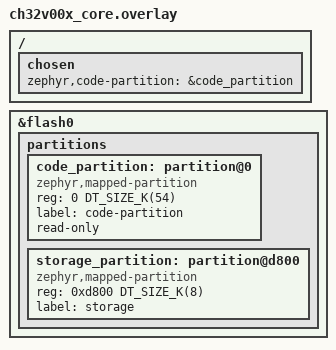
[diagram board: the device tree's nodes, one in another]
/*
 * SPDX-FileCopyrightText: Copyright Michael Hope <michaelh@juju.nz>
 *
 * SPDX-License-Identifier: Apache-2.0
 */

/ {
	chosen {
		zephyr,code-partition = &code_partition;
	};
};

&flash0 {
	partitions {
		ranges;
		#address-cells = <1>;
		#size-cells = <1>;

		code_partition: partition@0 {
			compatible = "zephyr,mapped-partition";
			reg = <0 DT_SIZE_K(54)>;
			label = "code-partition";
			read-only;
		};

		storage_partition: partition@d800 {
			compatible = "zephyr,mapped-partition";
			reg = <0xd800 DT_SIZE_K(8)>;
			label = "storage";
		};
	};
};
